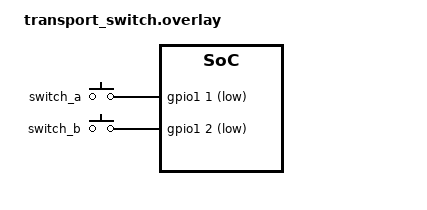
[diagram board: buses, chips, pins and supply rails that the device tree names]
/ {
    /* 3-position slide switch (SPDT ON-OFF-ON), common pin to GND:
     *   switch_a to GND -> BLE transport
     *   switch_b to GND -> ESB (2.4GHz) transport
     *   neither         -> USB-only (all radios off)
     * Pins: the extra mid-board pads of the ProMicro nRF52840 clone
     * (silk labels 101 = P1.01 and 102 = P1.02). */
    transport-switch {
        compatible = "gpio-keys";
        switch_a { gpios = <&gpio1 1 (GPIO_PULL_UP | GPIO_ACTIVE_LOW)>; };
        switch_b { gpios = <&gpio1 2 (GPIO_PULL_UP | GPIO_ACTIVE_LOW)>; };
    };
};
